AUTOSAR XML (schema 00048)
package /HuaweiMDC/FunctionalSoftware/Odometry/Execution
  executable OdometryExecutable
    root sw component prototype OdometryRootSwComponent: application-type=OdometryApplicationSwComponent
package /HuaweiMDC/FunctionalSoftware/Odometry/SwComponent
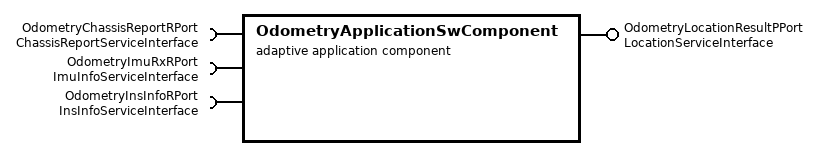
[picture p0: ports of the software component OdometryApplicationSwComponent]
  adaptive application sw component type OdometryApplicationSwComponent
    require port OdometryChassisReportRPort: required-interface=ChassisReportServiceInterface
    require port OdometryImuRxRPort: required-interface=ImuInfoServiceInterface
    require port OdometryInsInfoRPort: required-interface=InsInfoServiceInterface
    provide port OdometryLocationResultPPort: provided-interface=LocationServiceInterface
